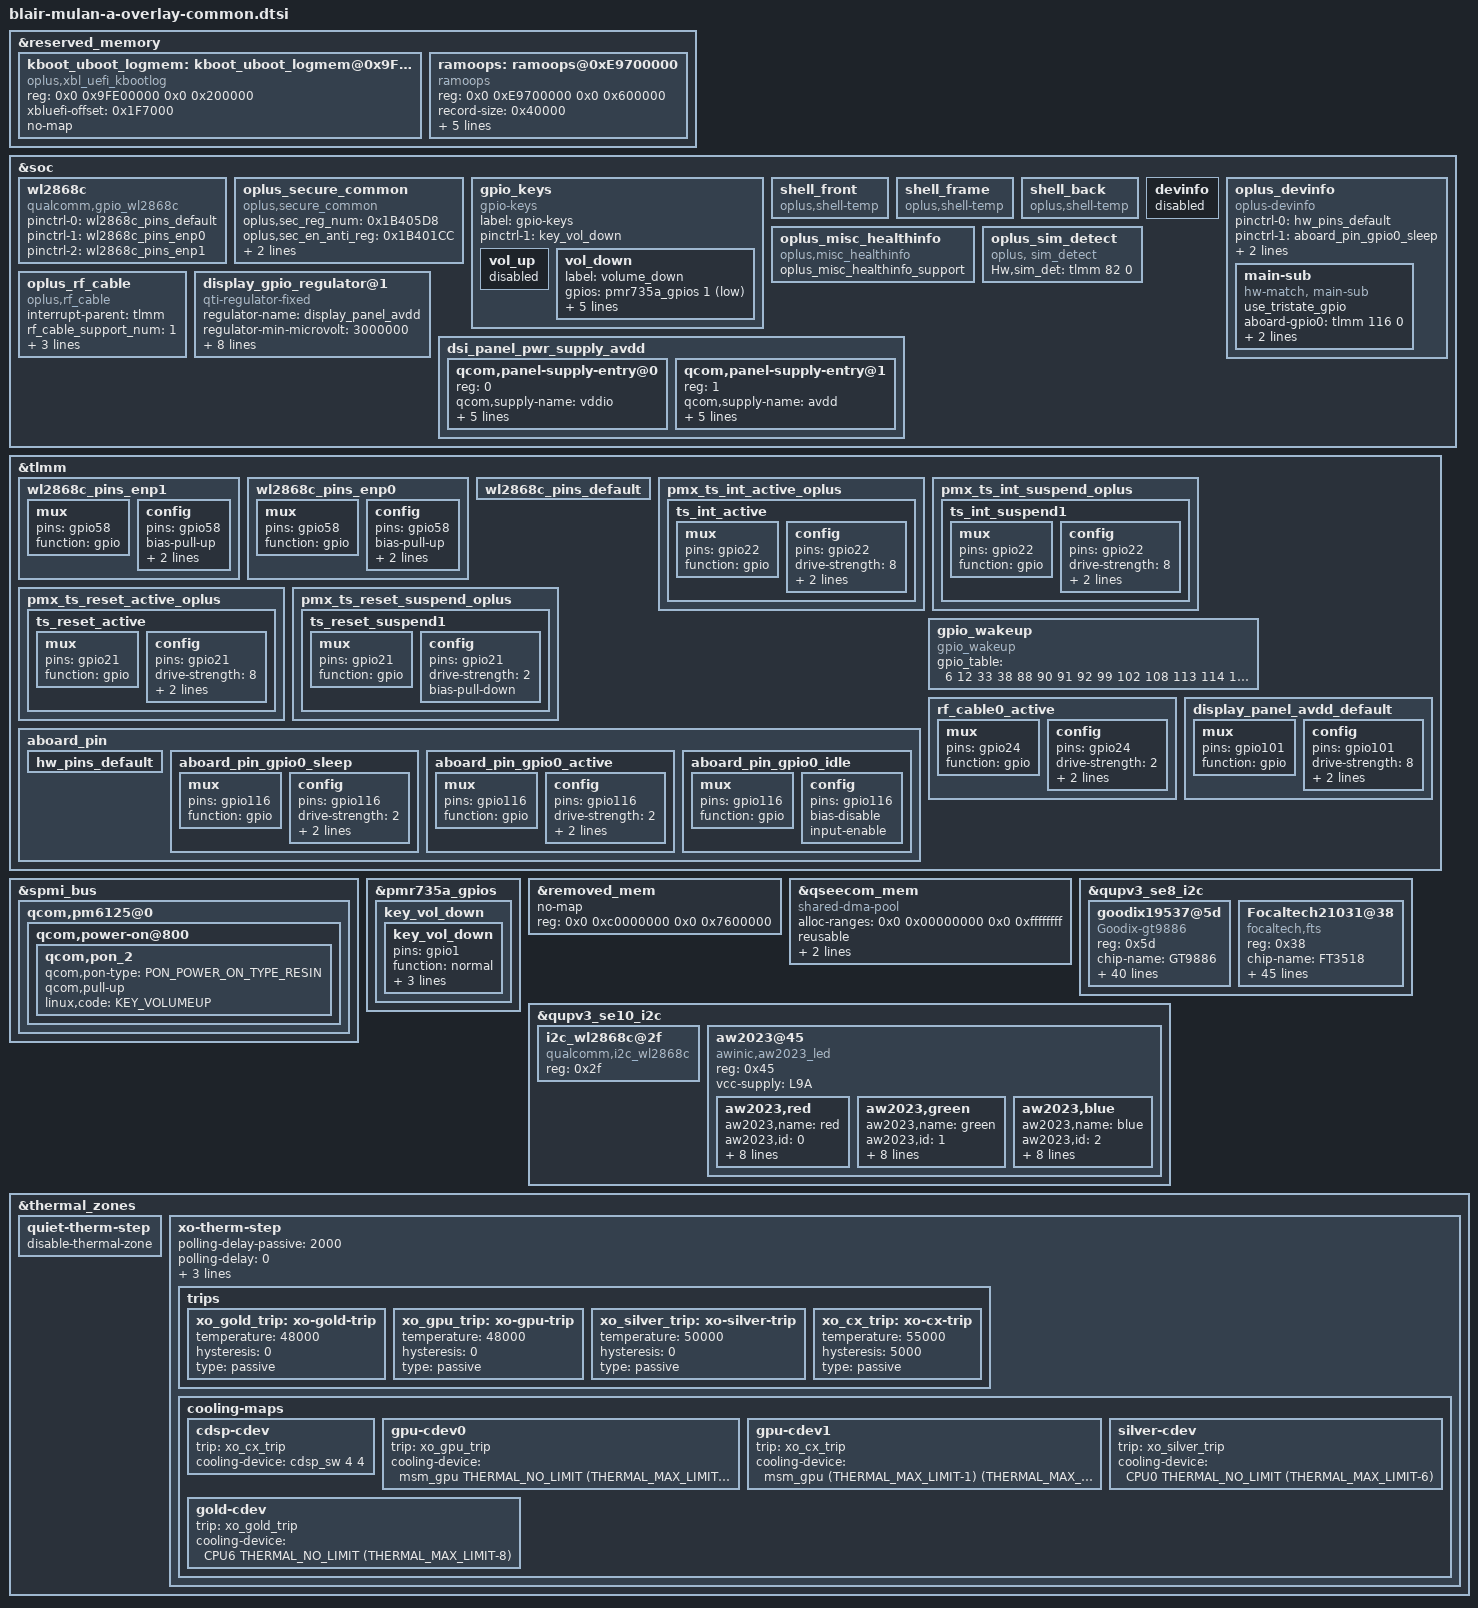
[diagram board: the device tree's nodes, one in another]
#include "../qcom/blair-qrd-nopmi.dtsi"

/* #ifdef OPLUS_ARCH_EXTENDS */
#include "blair-mulan-a-audio-overlay.dtsi"
/* #endif OPLUS_ARCH_EXTENDS */
/* DTBO: Platform common generic overlay */

&reserved_memory {
	//xbl_uefi_mem address get from: PcdEmbeddedFdBaseAddress +
	//SERIAL_BUFFER_OFFSET = 0x9FC00000 + 0x3F7000 = 0x9FFF7000
	//kernel boot log: 0x9FE00000~ 0x9FFF6FFF, xbl-uefi log: 0x9FFF7000 ~ 0x9FFFFFFF
	kboot_uboot_logmem: kboot_uboot_logmem@0x9FE00000 {
		reg = <0x0 0x9FE00000 0x0 0x200000>;
		compatible = "oplus,xbl_uefi_kbootlog";
		xbluefi-offset = <0x1F7000>;
		no-map;
	};

	//#if IS_ENABLED(CONFIG_OPLUS_FEATURE_DUMP_DEVICE_INFO)
	ramoops: ramoops@0xE9700000 {
		compatible = "ramoops";
		reg = <0x0 0xE9700000 0x0 0x600000>;  //6M
		record-size  = <0x40000>; //256k
		console-size = <0x40000>; //256k
		ftrace-size  = <0x100000>; //1M
		pmsg-size    = <0x100000>; //1M
		devinfo-size = <0x8000>;  //32k
		ecc-size     = <0x0>;
	 };
};

&soc {
	wl2868c:wl2868c {
		compatible = "qualcomm,gpio_wl2868c";
		pinctrl-names = "default", "wl2868c_gpio_enp0", "wl2868c_gpio_enp1";
		pinctrl-0 = <&wl2868c_pins_default>;
		pinctrl-1 = <&wl2868c_pins_enp0>;
		pinctrl-2 = <&wl2868c_pins_enp1>;
		status = "okay";
	};
};

&tlmm {
	wl2868c_pins_enp1: wl2868c_pins_enp1 {
		mux {
			pins = "gpio58";
			function = "gpio";
		};

		config {
			pins = "gpio58";
			bias-pull-up;
			output-low;
			drive-strength = <2>;
		};
	};

	wl2868c_pins_enp0: wl2868c_pins_enp0 {
		mux {
			pins = "gpio58";
			function = "gpio";
		};

		config {
			pins = "gpio58";
			bias-pull-up;
			output-high;
			drive-strength = <2>;
		};
	};

	wl2868c_pins_default: wl2868c_pins_default {
	};
};

&soc{
	oplus_secure_common {
		compatible = "oplus,secure_common";
		oplus,sec_reg_num = <0x1B405D8>;
		oplus,sec_en_anti_reg = <0x1B401CC>;
		oplus,sec_override1_reg = <0x7860C0>;
		oplus,override1_en_value = <0x1>;
	};
};

&soc {
/*#ifdef OPLUS_FEATURE_TP_BASIC*/
	gpio_keys {
		compatible = "gpio-keys";
		label = "gpio-keys";

		pinctrl-names = "default";
		pinctrl-1 = <&key_vol_down>;
		/* using volume down config update the default value */

		vol_up {
                status="disabled";
		};

		vol_down {
			label = "volume_down";
			gpios = <&pmr735a_gpios 1 GPIO_ACTIVE_LOW>;
			linux,input-type = <1>;
			linux,code = <KEY_VOLUMEDOWN>;
			gpio-key,wakeup;
			debounce-interval = <15>;
			linux,can-disable;
		};
	};
};

&spmi_bus {
	qcom,pm6125@0 {
		qcom,power-on@800 {
/*#ifdef OPLUS_FEATURE_TP_BASIC*/
			qcom,pon_2 {
					qcom,pon-type = <PON_POWER_ON_TYPE_RESIN>;
					qcom,pull-up;
					linux,code = <KEY_VOLUMEUP>;
			};
/*#endif OPLUS_FEATURE_TP_BASIC*/
		};
	};
};

&pmr735a_gpios {
	key_vol_down {
		key_vol_down: key_vol_down {
			pins = "gpio1";
			function = "normal";
			input-enable;
			bias-pull-up;
			power-source = <1>;
		};
	};
};

/* #ifdef OPLUS_FEATURE_CAMERA_COMMON */
//#include "camera/blair-camera-sensor-mtp.dtsi"
/* #endif OPLUS_FEATURE_CAMERA_COMMON */

//#ifdef OPLUS_FEATURE_FINGERPRINT
&soc{
	//#ifdef OPLUS_FEATURE_THERMAL_HORAE
	shell_front {
		compatible = "oplus,shell-temp";
	};

	shell_frame {
		compatible = "oplus,shell-temp";
	};

	shell_back {
		compatible = "oplus,shell-temp";
	};
	//#endif /* OPLUS_FEATURE_THERMAL_HORAE */
};

&removed_mem {
	no-map;
	//reg = <0x0 0xc0000000 0x0 0x5100000>;
	reg = <0x0 0xc0000000 0x0 0x7600000>;
};

&qseecom_mem {
	compatible = "shared-dma-pool";
	alloc-ranges = <0x0 0x00000000 0x0 0xffffffff>;
	reusable;
	alignment = <0x0 0x400000>;
	//size = <0x0 0x1400000>;
	size = <0x0 0x5C00000>;
};
//#endif /*OPLUS_FEATURE_FINGERPRINT*

//#ifdef OPLUS_FEATURE_TP_BASIC
&soc {
	devinfo {
		status = "disabled";
	};
	oplus_devinfo {
		compatible = "oplus-devinfo";

		pinctrl-names = "default", "sleep", "active", "idle";
		pinctrl-0 = <&hw_pins_default>;
		pinctrl-1 = <&aboard_pin_gpio0_sleep>;
		pinctrl-2 = <&aboard_pin_gpio0_active>;
		pinctrl-3 = <&aboard_pin_gpio0_idle>;
		main-sub {
			use_tristate_gpio;
			compatible = "hw-match, main-sub";
			aboard-gpio0 = <&tlmm 116 0>;
			aboard-patterns = <0 0 0 2>;	/*0[high-resistance] 1[pull-down] 2[pull-up]*/
			/*main board*/
			match-projects = <22041 22042 22241 22242>;
		};
	};

	oplus_misc_healthinfo:oplus_misc_healthinfo {
		compatible = "oplus,misc_healthinfo";
		oplus_misc_healthinfo_support;
	};

    //#ifdef OPLUS_FEATURE_TP_BASIC
	oplus_sim_detect {
		compatible = "oplus, sim_detect";
		Hw,sim_det = <&tlmm 82 0>;
	};
    //#endif /* OPLUS_FEATURE_TP_BASIC */
};

&tlmm {
	/* add pingrp for touchscreen */
	pmx_ts_int_active_oplus {
		ts_int_active: ts_int_active {
			mux {
				pins = "gpio22";
				function = "gpio";
			};

			config {
				pins = "gpio22";
				drive-strength = <8>;
				bias-disable;
				input-enable;
			};
		};
	};

	pmx_ts_int_suspend_oplus {
		ts_int_suspend1: ts_int_suspend1 {
			mux {
				pins = "gpio22";
				function = "gpio";
			};

			config {
				pins = "gpio22";
				drive-strength = <8>;
				//bias-pull-down;
				bias-pull-up;
				input-enable;
			};
		};
	};

	pmx_ts_reset_active_oplus {
		ts_reset_active: ts_reset_active {
			mux {
				pins = "gpio21";
				function = "gpio";
			};

			config {
				pins = "gpio21";
				drive-strength = <8>;
				output-low;
				bias-disable;
			};
		};
	};

	pmx_ts_reset_suspend_oplus {
		ts_reset_suspend1: ts_reset_suspend1 {
			mux {
				pins = "gpio21";
				function = "gpio";
			};

			config {
				pins = "gpio21";
				drive-strength = <2>;
				bias-pull-down;
			};
		};
	};


	//#ifdef OPLUS_FEATURE_TP_BASIC
        aboard_pin {
		hw_pins_default:hw_pins_default {
		};

		aboard_pin_gpio0_sleep:aboard_pin_gpio0_sleep {
			mux {
				pins = "gpio116";
				function = "gpio";
			};
			config {
				pins = "gpio116";
				drive-strength = <2>;
				bias-pull-down;
				input-enable;
			};
		};

		aboard_pin_gpio0_active:aboard_pin_gpio0_active {
			mux {
				pins = "gpio116";
				function = "gpio";
			};
			config {
				pins = "gpio116";
				drive-strength = <2>;
				bias-pull-up;
				input-enable;
			};
		};

		aboard_pin_gpio0_idle:aboard_pin_gpio0_idle {
			mux {
				pins = "gpio116";
				function = "gpio";
			};
			config {
				pins = "gpio116";
				bias-disable;
				input-enable;
			};
		};
	};
	//#endif /*OPLUS_FEATURE_TP_BASIC*/
};

&qupv3_se8_i2c {
	#address-cells = <1>;
	#size-cells = <0>;

	status = "ok";

	goodix19537@5d {
		compatible = "Goodix-gt9886";
		reg = <0x5d>;
		chip-name = "GT9886";

		/* Interrupt && Irq-gpio */
		interrupt-parent = <&tlmm>;
		interrupts = <22 0x2002>;

		/* Power Config */
		enable2v8_gpio = <&tlmm 102 0x1>;
		vcc_1v8-supply = <&L13A>;
		vdd_2v8_volt = <3008000>;

		/* Interrupt && Irq-gpio */
		irq-gpio = <&tlmm 22 0x2002>;
		reset-gpio = <&tlmm 21 0x1>;
		pinctrl-names = "default";
		pinctrl-0 = <&ts_int_active &ts_reset_active>;

		touchpanel,max-num-support = <10>;
		touchpanel,tx-rx-num = <16 34>;
		touchpanel,panel-coords = <5400 12000>;
		touchpanel,display-coords = <1080 2400>;
		touchpanel,touchmajor-limit = <0 270>;
		touchpanel,single-optimized-time = <8>;

		vid_len = <2>;
		project_id = <22241>;
		panel_type = <8>;
		tp_type = <8>;
		firmware_name = "0xAA30800";
		platform_support_project = <22041 22042 22241 22242>;
		platform_support_project_dir = <22241 22241 22241 22241>;
		platform_support_project_commandline = "default_commandline","default_commandline","default_commandline","default_commandline";

		/* SW Support Feature Control */
		register-is-16bit;
		black_gesture_support;
		fw_edge_limit_support;
		pressure_report_support;
		charger_pump_support;
		game_switch_support;
		smart_gesture_support;
		fw_update_app_support;
		fingerprint_underscreen_support;
		esd_handle_support;
		goodix_detail_debug_info_support;
		health_monitor_support;
		/*
		 *Virtual Key Config:
		 *1:touchpanel,button-type: <virtualkey_type  supportted_button-map>
		 *virtualkey_type:
		 *Type 1: using board_properties
		 *Type 2: using same IC (button zone&& touch zone are seprate)
		 *Type 3: using diffrent IC (button zone&& touch zone are seprate)
		 *Type 4: No need of virtual key process
		 *supportted_button-map:select|menu|home|back
		 *
		 *2:touchpanel,button-map
		 *type (X1,Y1)(X2,Y2)(X3,Y3)(Width_X,Hight_Y)--Only when button-type is 0
		 */
		touchpanel,button-type = <4>;
		touchpanel.button-TRx = <0 0>;
	};

	Focaltech21031@38 {
		compatible = "focaltech,fts";
		reg = <0x38>;
		chip-name = "FT3518";

		/* Interrupt && Irq-gpio */
		interrupt-parent = <&tlmm>;
		interrupts = <22 0x2002>;

		/* Power Config */
		enable2v8_gpio = <&tlmm 102 0x1>;
		vcc_1v8-supply = <&L13A>;
		vdd_2v8_volt = <3008000>;

		/* Interrupt && Irq-gpio */
                /* Other HW Resource */
		irq-gpio = <&tlmm 22 0x2002>;
		reset-gpio = <&tlmm 21 0x1>;
		pinctrl-names = "default";
		pinctrl-0 = <&ts_int_active &ts_reset_active>;

		touchpanel,max-num-support = <10>;
		touchpanel,tx-rx-num = <16 34>;
		touchpanel,panel-coords = <4320 9600>;
		touchpanel,display-coords = <1080 2400>;
		touchpanel,touchmajor-limit = <0 216>;
		touchpanel,smooth-level = <255 0 10 20 35 50>;
		touchpanel,smooth-level-charging = <255 15 20 25 45 60>;
		touchpanel,sensitive-level = <255 18 14 10 5 0>;
		touchpanel,single-optimized-time = <8>;
		touchpanel,high-frame-rate-time = <20>;

		project_id = <22041>;
		panel_type = <8>;
		tp_type = <8>;
		firmware_name = "0xAA30800";
		platform_support_project = <22041 22042 22241 22242>;
		platform_support_project_dir = <22041 22041 22041 22041>;
		platform_support_project_commandline = "default_commandline","default_commandline","default_commandline","default_commandline";

		/* SW Support Feature Control */
		black_gesture_support;
		fw_edge_limit_support;
		pressure_report_support;
		charger_pump_support;
		game_switch_support;
		smart_gesture_support;
		fw_update_app_support;
		fingerprint_underscreen_support;
		headset_pump_support;
		//esd_handle_support;
		new_set_irq_wake_support;
		irq_need_dev_resume_ok;
		high_resolution_support;
		health_monitor_support;
		/*
		*Virtual Key Config:
		*1:touchpanel,button-type: <virtualkey_type  supportted_button-map>
		*virtualkey_type:
		*Type 1: using board_properties
		*Type 2: using same IC (button zone&& touch zone are seprate)
		*Type 3: using diffrent IC (button zone&& touch zone are seprate)
		*Type 4: No need of virtual key process
		*supportted_button-map:select|menu|home|back
		*
		*2:touchpanel,button-map
		*type (X1,Y1)(X2,Y2)(X3,Y3)(Width_X,Hight_Y)--Only when button-type is 0
		*/
		touchpanel,button-type = <4>;
		touchpanel.button-TRx = <0 0>;
	};
};

&qupv3_se10_i2c {
	#address-cells = <1>;
	#size-cells = <0>;

	status = "okay";

	i2c_wl2868c@2f{
		compatible = "qualcomm,i2c_wl2868c";
		reg = <0x2f>;
		status = "okay";
	};

	aw2023@45 {
		compatible = "awinic,aw2023_led";
		reg = <0x45>;
		vcc-supply = <&L9A>;

		aw2023,red {
			aw2023,name = "red";
			aw2023,id = <0>;
			aw2023,imax = <1>;
			aw2023,led_default_trigger = "none";
			aw2023,brightness = <3>;
			aw2023,max-brightness = <15>;
			aw2023,rise-time-ms = <6>;
			aw2023,hold-time-ms = <0>;
			aw2023,fall-time-ms = <6>;
			aw2023,off-time-ms = <4>;
		};

		aw2023,green {
			aw2023,name = "green";
			aw2023,id = <1>;
			aw2023,imax = <1>;
			aw2023,led_default_trigger = "none";
			aw2023,brightness = <3>;
			aw2023,max-brightness = <15>;
			aw2023,rise-time-ms = <6>;
			aw2023,hold-time-ms = <0>;
			aw2023,fall-time-ms = <6>;
			aw2023,off-time-ms = <4>;
		};

		aw2023,blue {
			aw2023,name = "blue";
			aw2023,id = <2>;
			aw2023,imax = <1>;
			aw2023,led_default_trigger = "none";
			aw2023,brightness = <3>;
			aw2023,max-brightness = <15>;
			aw2023,rise-time-ms = <6>;
			aw2023,hold-time-ms = <0>;
			aw2023,fall-time-ms = <6>;
			aw2023,off-time-ms = <4>;
		};
	};
};

&tlmm {
	//Liu.Xu 2021/0926 add for disable wake-up function of NC-GPIO
	gpio_wakeup: gpio_wakeup {
		compatible = "gpio_wakeup";
		gpio_table = <6 12 33 38 88 90 91 92 99 102 108 113 114 115 116
                              7 8 9 48 51 59 84 85 86 107 117 118 152 153 154 155>;
	};
};

//Wei.Tang 2021/09/23 modify for rf_cable
&tlmm {
	rf_cable0_active: rf_cable0_active {
		mux {
			pins = "gpio24";
			function = "gpio";
		};
		config {
			pins = "gpio24";
			drive-strength = <2>;
			input-enable;
			bias-pull-up;
		};
	};
};

&soc {
	oplus_rf_cable {
		compatible = "oplus,rf_cable";
		interrupt-parent = <&tlmm>;
		rf_cable_support_num = <1>;
		rf,cable0-gpio = <&tlmm 24 0>;
		rf,cable-support-timer = <0>;
		pinctrl-names = "rf_cable_active";
		pinctrl-0 = <&rf_cable0_active>;
	};
};

//#ifdef OPLUS_TEMP_NTC
&thermal_zones {
	quiet-therm-step {
		disable-thermal-zone;
	};

	xo-therm-step {
		polling-delay-passive = <2000>;
		polling-delay = <0>;
		thermal-governor = "step_wise";
		thermal-sensors = <&pm6125_adc_tm ADC5_XO_THERM_100K_PU>;

		trips {
			xo_gold_trip: xo-gold-trip {
				temperature = <48000>;
				hysteresis = <0>;
				type = "passive";
			};

			xo_gpu_trip: xo-gpu-trip {
				temperature = <48000>;
				hysteresis = <0>;
				type = "passive";
			};

			xo_silver_trip: xo-silver-trip {
				temperature = <50000>;
				hysteresis = <0>;
				type = "passive";
			};

			xo_cx_trip: xo-cx-trip {
				temperature = <55000>;
				hysteresis = <5000>;
				type = "passive";
			};
		};

		cooling-maps {
			cdsp-cdev {
				trip = <&xo_cx_trip>;
				cooling-device = <&cdsp_sw 4 4>;
			};

			gpu-cdev0 {
				trip = <&xo_gpu_trip>;
				/* throttle to 650000000Hz */
				cooling-device = <&msm_gpu THERMAL_NO_LIMIT
							(THERMAL_MAX_LIMIT-3)>;
			};

			gpu-cdev1 {
				trip = <&xo_cx_trip>;
				/* throttle to 390000000Hz */
				cooling-device = <&msm_gpu (THERMAL_MAX_LIMIT-1)
							(THERMAL_MAX_LIMIT-1)>;
			};

			silver-cdev {
				trip = <&xo_silver_trip>;
				/* throttle to 1516800KHz */
				cooling-device = <&CPU0 THERMAL_NO_LIMIT
							(THERMAL_MAX_LIMIT-6)>;
			};

			gold-cdev {
				trip = <&xo_gold_trip>;
				/* throttle to 2054400KHz */
				cooling-device = <&CPU6 THERMAL_NO_LIMIT
							(THERMAL_MAX_LIMIT-8)>;
			};
		};
	};
};

&tlmm {
	display_panel_avdd_default {
		mux {
			pins = "gpio101";
			function = "gpio";
		};

		config {
			pins = "gpio101";
			drive-strength = <8>;
			bias-disable = <0>;
			output-high;
		};
	};
};

&soc {
	display_gpio_regulator@1 {
		compatible = "qti-regulator-fixed";
		regulator-name = "display_panel_avdd";
		regulator-min-microvolt = <3000000>;
		regulator-max-microvolt = <3000000>;
		regulator-enable-ramp-delay = <233>;
		gpio = <&tlmm 101 0>;
		enable-active-high;
		regulator-boot-on;
		proxy-supply = <&display_panel_avdd>;
		qcom,proxy-consumer-enable;
		pinctrl-names = "default";
		pinctrl-0 = <&display_panel_avdd_default>;
	};

	dsi_panel_pwr_supply_avdd {
		#size-cells = <0>;
		#address-cells = <1>;

		qcom,panel-supply-entry@0 {
			reg = <0>;
			qcom,supply-name = "vddio";
			qcom,supply-min-voltage = <1800000>;
			qcom,supply-max-voltage = <1800000>;
			qcom,supply-enable-load = <62000>;
			qcom,supply-disable-load = <80>;
			qcom,supply-post-on-sleep = <0>;
		};

		qcom,panel-supply-entry@1 {
			reg = <1>;
			qcom,supply-name = "avdd";
			qcom,supply-min-voltage = <3000000>;
			qcom,supply-max-voltage = <3000000>;
			qcom,supply-enable-load = <857000>;
			qcom,supply-disable-load = <0>;
			qcom,supply-post-on-sleep = <0>;
		};

	};
};
//#endif
